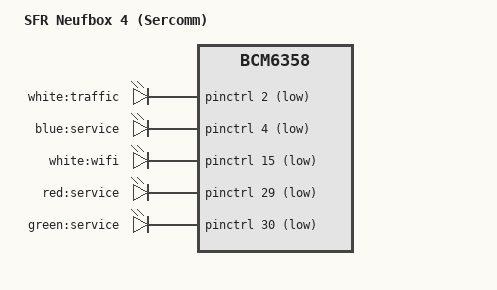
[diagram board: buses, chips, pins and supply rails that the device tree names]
#include "bcm6358-sfr-neufbox-4.dtsi"

/ {
	model = "SFR Neufbox 4 (Sercomm)";
	compatible = "sfr,neufbox-4-sercomm-r0", "brcm,bcm6358";

	leds {
		compatible = "gpio-leds";

		traffic_white {
			label = "white:traffic";
			gpios = <&pinctrl 2 1>;
		};
		service_blue {
			label = "blue:service";
			gpios = <&pinctrl 4 1>;
		};
		wifi_white {
			label = "white:wifi";
			gpios = <&pinctrl 15 1>;
		};
		service_red {
			label = "red:service";
			gpios = <&pinctrl 29 1>;
		};
		service_green {
			label = "green:service";
			gpios = <&pinctrl 30 1>;
		};
	};
};
